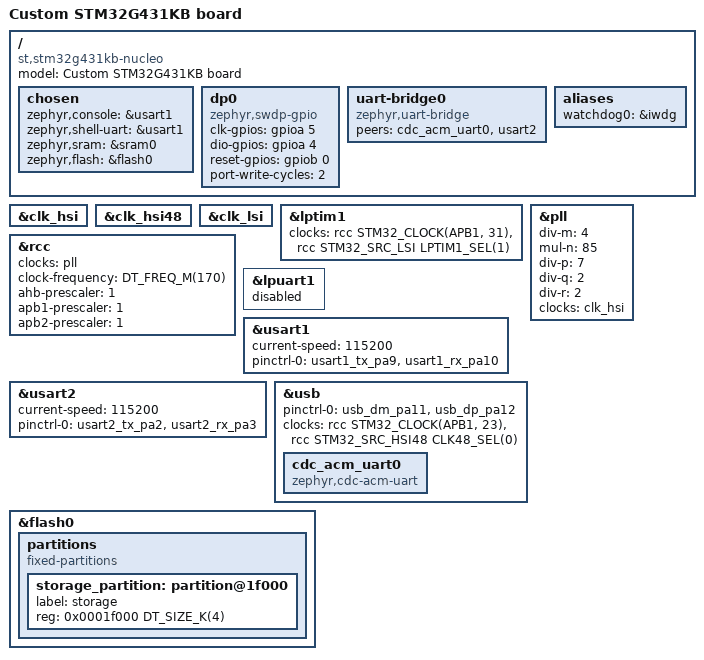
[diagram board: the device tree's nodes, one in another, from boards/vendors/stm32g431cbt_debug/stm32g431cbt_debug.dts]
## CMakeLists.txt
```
#-------------------------------------------------------------------------------
# Zephyr Example Application
#
# Copyright (c) 2021 Nordic Semiconductor ASA
# SPDX-License-Identifier: Apache-2.0
list(APPEND BOARD_ROOT ${CMAKE_CURRENT_SOURCE_DIR})
set(BOARD stm32g431cbt_debug)

cmake_minimum_required(VERSION 3.13.1)
find_package(Zephyr REQUIRED HINTS $ENV{ZEPHYR_BASE})

project(app LANGUAGES C)

include(${ZEPHYR_BASE}/samples/subsys/usb/common/common.cmake)

target_sources(app PRIVATE 
    src/main.c
)
```

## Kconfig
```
# Copyright (c) 2021 Nordic Semiconductor ASA
# SPDX-License-Identifier: Apache-2.0
#
# This file is the application Kconfig entry point. All application Kconfig
# options can be defined here or included via other application Kconfig files.
# You can browse these options using the west targets menuconfig (terminal) or
# guiconfig (GUI).

menu "Zephyr"
source "Kconfig.zephyr"
endmenu
```

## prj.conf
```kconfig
CONFIG_USB_DEVICE_STACK_NEXT=y
CONFIG_CDC_ACM_SERIAL_INITIALIZE_AT_BOOT=n
CONFIG_SAMPLE_USBD_PRODUCT="Zephyr CMSIS-DAP"
CONFIG_SAMPLE_USBD_PID=0x0204
CONFIG_SAMPLE_USBD_20_EXTENSION_DESC=y

CONFIG_SERIAL=y
CONFIG_UART_LINE_CTRL=y
CONFIG_UART_USE_RUNTIME_CONFIGURE=y
CONFIG_USBD_CDC_ACM_CLASS=y
CONFIG_CDC_ACM_SERIAL_INITIALIZE_AT_BOOT=n


CONFIG_LOG=y
CONFIG_LOG_DEFAULT_LEVEL=2

CONFIG_DAP_LOG_LEVEL_INF=y
CONFIG_DP_DRIVER_LOG_LEVEL_INF=y
CONFIG_DAP=y
CONFIG_DAP_BACKEND_USB=y
CONFIG_GPIO=y
```

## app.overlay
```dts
// / {
//     chosen {
//         zephyr,console = &cdc_acm_uart0;
//         zephyr,shell-uart = &cdc_acm_uart0;
//     };
//     // leds { // Trick to make enumeration work by toggling the D+ pin
//     //     compatible = "gpio-leds";
//     //     usb_dp: usb_dp {
//     //         label = "USB D+ pin";
//     //         gpios = <&gpioa 12 GPIO_ACTIVE_HIGH>;
//     //     };
//     // };

//     dp0 {
//         compatible = "zephyr,swdp-gpio";
// //        compatible = "arm,cmsis-dap";
//         status = "okay";
//         clk-gpios = <&gpioa 5 GPIO_ACTIVE_HIGH>;
//         dio-gpios  = <&gpioa 4 GPIO_PULL_UP>;
//         reset-gpios = <&gpiob 0 GPIO_ACTIVE_HIGH>;
//         port-write-cycles = <2>;
//     };

//     uart-bridge0 {
//         compatible = "zephyr,uart-bridge";
//         peers = <&cdc_acm_uart0 &usart2>;
// 	};
// };

// &clk_hsi {
//     status = "okay";
// };

// &clk_hsi48 {
//     status = "okay";
// };

// &pll {
//     div-m = <4>;
//     mul-n = <85>;
//     div-p = <2>;
//     div-q = <4>;
//     div-r = <2>;
//     clocks = <&clk_hsi>;
//     status = "okay";
// };

// &rcc {
//     clocks = <&pll>;
//     clock-frequency = <DT_FREQ_M(170)>;
//     ahb-prescaler = <1>;
//     apb1-prescaler = <1>;
//     apb2-prescaler = <1>;
// };


// &usart1 {
//     status = "okay";
//     current-speed = <115200>;
//     pinctrl-0 = <&usart1_tx_pa9 &usart1_rx_pa10>;
//     pinctrl-names = "default";
// };

// &usart2 {
//     status = "okay";
//     current-speed = <115200>;
//     pinctrl-0 = <&usart2_tx_pa2 &usart2_rx_pa3>;
//     pinctrl-names = "default";
// };


// zephyr_udc0: &usb {
//     status = "okay";
//     pinctrl-0 = <&usb_dm_pa11 &usb_dp_pa12>;
//     pinctrl-names = "default";

//     cdc_acm_uart0: cdc_acm_uart0 {
//         compatible = "zephyr,cdc-acm-uart";
//     };
// };
```

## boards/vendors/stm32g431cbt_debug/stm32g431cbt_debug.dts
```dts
/*
 * Copyright (c) 2024 Klaus Nagel, <nagelkl01@gmail.com>
 *
 * SPDX-License-Identifier: Apache-2.0
 */

/dts-v1/;
#include <st/g4/stm32g431Xb.dtsi>
#include <st/g4/stm32g431k(6-8-b)tx-pinctrl.dtsi>

/ {
	model = "Custom STM32G431KB board";
	compatible = "st,stm32g431kb-nucleo";

	chosen {
		zephyr,console = &usart1;
		zephyr,shell-uart = &usart1;
		zephyr,sram = &sram0;
		zephyr,flash = &flash0;
	};

	dp0 {
		compatible = "zephyr,swdp-gpio";
	//        compatible = "arm,cmsis-dap";
		status = "okay";
		clk-gpios = <&gpioa 5 GPIO_ACTIVE_HIGH>;
		dio-gpios  = <&gpioa 4 GPIO_PULL_UP>;
		reset-gpios = <&gpiob 0 GPIO_ACTIVE_HIGH>;
		port-write-cycles = <2>;
	};

	uart-bridge0 {
		compatible = "zephyr,uart-bridge";
		peers = <&cdc_acm_uart0 &usart2>;
	};

	aliases {
		watchdog0 = &iwdg;
	};
};

&clk_hsi {
	status = "okay";
};

&clk_hsi48 {
    status = "okay";
};

&clk_lsi {
	status = "okay";
};


stm32_lp_tick_source: &lptim1 {
	clocks = <&rcc STM32_CLOCK(APB1, 31)>,
		 <&rcc STM32_SRC_LSI LPTIM1_SEL(1)>;
	status = "okay";
};

/* Adjust the pll for a SYSTEM Clock of 170MHz  */
&pll {
	div-m = <4>;
	mul-n = <85>;
	div-p = <7>;
	div-q = <2>;
	div-r = <2>;
	clocks = <&clk_hsi>;
	status = "okay";
};

&rcc {
	clocks = <&pll>;
	clock-frequency = <DT_FREQ_M(170)>;
	ahb-prescaler = <1>;
	apb1-prescaler = <1>;
	apb2-prescaler = <1>;
};

// &lpuart1 {
// 	pinctrl-0 = <&lpuart1_tx_pa2 &lpuart1_rx_pa3>;
// 	pinctrl-names = "default";
// 	current-speed = <115200>;
// 	status = "okay";
// };

&lpuart1 {
	status = "disabled";
};

&usart1 {
    status = "okay";
    current-speed = <115200>;
    pinctrl-0 = <&usart1_tx_pa9 &usart1_rx_pa10>;
    pinctrl-names = "default";
};

&usart2 {
    status = "okay";
    current-speed = <115200>;
    pinctrl-0 = <&usart2_tx_pa2 &usart2_rx_pa3>;
    pinctrl-names = "default";
};

// &i2c2 {
// 	pinctrl-0 = <&i2c2_scl_pa9 &i2c2_sda_pa8>;
// 	pinctrl-names = "default";
// 	status = "okay";
// };

zephyr_udc0: &usb {
    status = "okay";
    pinctrl-0 = <&usb_dm_pa11 &usb_dp_pa12>;
    pinctrl-names = "default";
    clocks = <&rcc STM32_CLOCK(APB1, 23)>,
		 <&rcc STM32_SRC_HSI48 CLK48_SEL(0)>;

    cdc_acm_uart0: cdc_acm_uart0 {
        compatible = "zephyr,cdc-acm-uart";
    };
};

&flash0 {
	partitions {
		compatible = "fixed-partitions";
		#address-cells = <1>;
		#size-cells = <1>;

		/* Set 4Kb of storage at the end of the 128Kb of flash */
		storage_partition: partition@1f000 {
			label = "storage";
			reg = <0x0001f000 DT_SIZE_K(4)>;
		};
	};
};
```

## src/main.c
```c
/*
 * Copyright (c) 2025
 *
 * SPDX-License-Identifier: Apache-2.0
 */

/**
 * @file 
 */

#include <zephyr/kernel.h>
#include <zephyr/device.h>
#include <zephyr/drivers/uart.h>
#include <zephyr/drivers/gpio.h>
#include <zephyr/usb/usb_device.h>
#include <zephyr/usb/class/usb_hid.h>
#include <zephyr/sys/ring_buffer.h>
#include <zephyr/logging/log.h>

LOG_MODULE_REGISTER(main, LOG_LEVEL_INF);

static const struct device *usb_cdc_dev = DEVICE_DT_GET(DT_NODELABEL(cdc_acm_uart0));
static const struct device *hw_uart_dev = DEVICE_DT_GET(DT_NODELABEL(usart1));
static const struct device *hid_dev;

#define RING_BUF_SIZE 1024
RING_BUF_DECLARE(cdc_to_hw_ring, RING_BUF_SIZE);
RING_BUF_DECLARE(hw_to_cdc_ring, RING_BUF_SIZE);

/* CMSIS-DAP v1 HID Report Descriptor */
static const uint8_t hid_report_desc[] = {
    0x06, 0x00, 0xFF,  /* Usage Page (Vendor Defined 0xFF00) */
    0x09, 0x01,        /* Usage (Vendor Usage 1) */
    0xA1, 0x01,        /* Collection (Application) */
    0x15, 0x00,        /* Logical Minimum (0) */
    0x26, 0xFF, 0x00,  /* Logical Maximum (255) */
    0x75, 0x08,        /* Report Size (8 bits) */
    0x95, 0x40,        /* Report Count (64 bytes) */
    0x09, 0x02,        /* Usage (Vendor Usage 2) */
    0x81, 0x02,        /* Input (Data, Var, Abs) */
    0x09, 0x03,        /* Usage (Vendor Usage 3) */
    0x91, 0x02,        /* Output (Data, Var, Abs) */
    0xC0               /* End Collection */
};

static void cdc_acm_cb(const struct device *dev, void *user_data)
{
    uint8_t buf[64];
    int read_len;

    while (uart_irq_update(dev) && uart_irq_is_pending(dev)) {
        if (uart_irq_rx_ready(dev)) {
            read_len = uart_fifo_read(dev, buf, sizeof(buf));
            if (read_len > 0) {
                ring_buf_put(&cdc_to_hw_ring, buf, read_len);
                uart_irq_tx_enable(hw_uart_dev);
            }
        }

        if (uart_irq_tx_ready(dev)) {
            uint8_t tx_buf[64];
            uint32_t bytes_to_send = ring_buf_get(&hw_to_cdc_ring, tx_buf, sizeof(tx_buf));

            if (bytes_to_send == 0) {
                uart_irq_tx_disable(dev);
            } else {
                uart_fifo_fill(dev, tx_buf, bytes_to_send);
            }
        }
    }
}

static void hw_uart_cb(const struct device *dev, void *user_data)
{
    uint8_t buf[64];
    int read_len;

    while (uart_irq_update(dev) && uart_irq_is_pending(dev)) {
        if (uart_irq_rx_ready(dev)) {
            read_len = uart_fifo_read(dev, buf, sizeof(buf));
            if (read_len > 0) {
                ring_buf_put(&hw_to_cdc_ring, buf, read_len);
                uart_irq_tx_enable(usb_cdc_dev);
            }
        }

        if (uart_irq_tx_ready(dev)) {
            uint8_t tx_buf[64];
            uint32_t bytes_to_send = ring_buf_get(&cdc_to_hw_ring, tx_buf, sizeof(tx_buf));

            if (bytes_to_send == 0) {
                uart_irq_tx_disable(dev);
            } else {
                uart_fifo_fill(dev, tx_buf, bytes_to_send);
            }
        }
    }
}

int main(void)
{
    int ret;
 
    if (!device_is_ready(usb_cdc_dev) || !device_is_ready(hw_uart_dev)) {
        LOG_ERR("UART or USB CDC devices not ready");
        return 0;
    }

    hid_dev = device_get_binding("HID_0");
    if (hid_dev == NULL) {
        LOG_ERR("Cannot get USB HID Device");
        return 0;
    }

    usb_hid_register_device(hid_dev, hid_report_desc, sizeof(hid_report_desc), NULL);
    usb_hid_init(hid_dev);

    ret = usb_enable(NULL);
    if (ret != 0) {
        LOG_ERR("Failed to enable USB stack (%d)", ret);
        return 0;
    }

    uart_irq_callback_set(usb_cdc_dev, cdc_acm_cb);
    uart_irq_callback_set(hw_uart_dev, hw_uart_cb);

    uart_irq_rx_enable(usb_cdc_dev);
    uart_irq_rx_enable(hw_uart_dev);

    LOG_INF("Composite USB Debugger active.");

    while (1) {
        k_msleep(1000);
    }

    return 0;
}
```

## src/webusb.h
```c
/*
 * Copyright (c) 2016-2019 Intel Corporation
 * Copyright (c) 2023-2024 Nordic Semiconductor ASA
 *
 * SPDX-License-Identifier: Apache-2.0
 */

#ifndef ZEPHYR_INCLUDE_WEBUSB_DESCRIPTOR_H
#define ZEPHYR_INCLUDE_WEBUSB_DESCRIPTOR_H

/*
 * WebUSB platform capability and WebUSB URL descriptor.
 * See https://wicg.github.io/webusb for reference.
 */

#define WEBUSB_REQ_GET_URL		0x02U
#define WEBUSB_DESC_TYPE_URL		0x03U
#define WEBUSB_URL_PREFIX_HTTP		0x00U
#define WEBUSB_URL_PREFIX_HTTPS		0x01U

#define SAMPLE_WEBUSB_VENDOR_CODE	0x01U
#define SAMPLE_WEBUSB_LANDING_PAGE	0x01U

struct usb_bos_webusb_desc {
	struct usb_bos_platform_descriptor platform;
	struct usb_bos_capability_webusb cap;
} __packed;

static const struct usb_bos_webusb_desc bos_cap_webusb = {
	/* WebUSB Platform Capability Descriptor:
	 * https://wicg.github.io/webusb/#webusb-platform-capability-descriptor
	 */
	.platform = {
		.bLength = sizeof(struct usb_bos_platform_descriptor)
			 + sizeof(struct usb_bos_capability_webusb),
		.bDescriptorType = USB_DESC_DEVICE_CAPABILITY,
		.bDevCapabilityType = USB_BOS_CAPABILITY_PLATFORM,
		.bReserved = 0,
		/* WebUSB Platform Capability UUID
		 * 3408b638-09a9-47a0-8bfd-a0768815b665
		 */
		.PlatformCapabilityUUID = {
			0x38, 0xB6, 0x08, 0x34,
			0xA9, 0x09,
			0xA0, 0x47,
			0x8B, 0xFD,
			0xA0, 0x76, 0x88, 0x15, 0xB6, 0x65,
		},
	},
	.cap = {
		.bcdVersion = sys_cpu_to_le16(0x0100),
		.bVendorCode = SAMPLE_WEBUSB_VENDOR_CODE,
		.iLandingPage = SAMPLE_WEBUSB_LANDING_PAGE
	}
};

/* WebUSB URL Descriptor, see https://wicg.github.io/webusb/#webusb-descriptors */
static const uint8_t webusb_origin_url[] = {
	/* bLength, bDescriptorType, bScheme, UTF-8 encoded URL */
	0x24, WEBUSB_DESC_TYPE_URL, WEBUSB_URL_PREFIX_HTTPS,
	'w', 'w', 'w', '.',
	'z', 'e', 'p', 'h', 'y', 'r', 'p', 'r', 'o', 'j', 'e', 'c', 't', '.',
	'o', 'r', 'g', '/',
};

static int webusb_to_host_cb(const struct usbd_context *const ctx,
			     const struct usb_setup_packet *const setup,
			     struct net_buf *const buf)
{
	LOG_INF("Vendor callback to host");

	if (setup->wIndex == WEBUSB_REQ_GET_URL) {
		uint8_t index = USB_GET_DESCRIPTOR_INDEX(setup->wValue);

		if (index != SAMPLE_WEBUSB_LANDING_PAGE) {
			return -ENOTSUP;
		}

		LOG_INF("Get URL request, index %u", index);
		net_buf_add_mem(buf, &webusb_origin_url,
				MIN(net_buf_tailroom(buf), sizeof(webusb_origin_url)));

		return 0;
	}

	return -ENOTSUP;
}

USBD_DESC_BOS_VREQ_DEFINE(bos_vreq_webusb, sizeof(bos_cap_webusb), &bos_cap_webusb,
			  SAMPLE_WEBUSB_VENDOR_CODE, webusb_to_host_cb, NULL);

#endif /* ZEPHYR_INCLUDE_WEBUSB_DESCRIPTOR_H */
```
